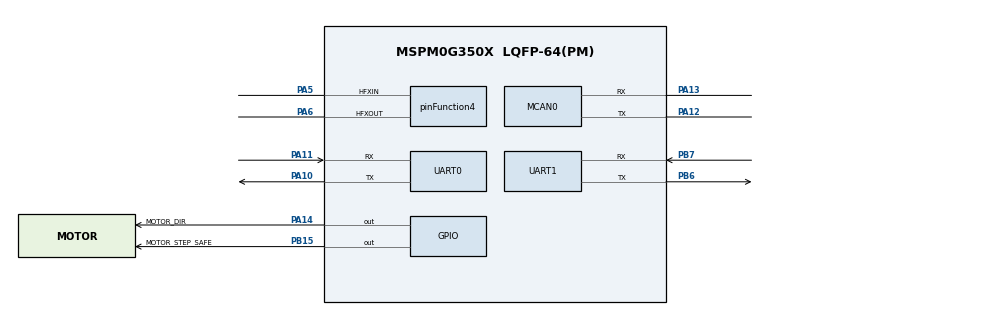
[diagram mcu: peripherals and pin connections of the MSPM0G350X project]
/**
 * @cliArgs --device "MSPM0G350X" --part "Default" --package "LQFP-64(PM)" --product "mspm0_sdk@2.10.00.04"
 * @versions {"tool":"1.27.1+4634"}
 */

/** Import only the system/debug, CAN, and project output modules. */
const Board         = scripting.addModule("/ti/driverlib/Board");
const GPIO          = scripting.addModule("/ti/driverlib/GPIO", {}, false);
const GPIOMotor     = GPIO.addInstance();
const MCAN          = scripting.addModule("/ti/driverlib/MCAN", {}, false);
const MCAN0         = MCAN.addInstance();
const SYSCTL        = scripting.addModule("/ti/driverlib/SYSCTL");
const UART          = scripting.addModule("/ti/driverlib/UART", {}, false);
const UART0         = UART.addInstance();
const UART1         = UART.addInstance();
const ProjectConfig = scripting.addModule("/ti/project_config/ProjectConfig");

/* Keep the validated external 40 MHz clock and 80 MHz HFCLK clock tree. */
const divider9       = system.clockTree["UDIV"];
divider9.divideValue = 2;

const gate7  = system.clockTree["MFCLKGATE"];
gate7.enable = true;

const mux4       = system.clockTree["EXHFMUX"];
mux4.inputSelect = "EXHFMUX_XTAL";

const mux8       = system.clockTree["HSCLKMUX"];
mux8.inputSelect = "HSCLKMUX_SYSPLL2X";

const mux12       = system.clockTree["SYSPLLMUX"];
mux12.inputSelect = "zSYSPLLMUX_HFCLK";

const pinFunction4                       = system.clockTree["HFXT"];
pinFunction4.inputFreq                   = 40;
pinFunction4.enable                      = true;
pinFunction4.peripheral.hfxInPin.$assign = "PA5";
pinFunction4.peripheral.hfxOutPin.$assign = "PA6";

/* CAN0: Classic CAN, 500 kbit/s, normal bus mode, standard ID 0x100 to FIFO0. */
MCAN0.$name                     = "MCAN0";
MCAN0.fdMode                    = false;
MCAN0.brsEnable                 = false;
MCAN0.loopbackMode              = "disabled";
MCAN0.desiredNomRate            = 500;
MCAN0.useCalcNomVal             = true;
MCAN0.lss                       = 2;
MCAN0.stdFiltElem               = "001";
MCAN0.stdFiltType               = "10";
MCAN0.stdFiltID1                = 0x100;
MCAN0.stdFiltID2                = 0x7FF;

/* Classic CAN uses 8-byte data elements; keep active message RAM sections disjoint. */
MCAN0.flesa                     = 8;
MCAN0.txStartAddr                = 16;
MCAN0.txBufNum                   = 3;
MCAN0.txBufElemSize              = "DL_MCAN_ELEM_SIZE_8BYTES";
MCAN0.txEventFIFOStartAddr       = 48;
MCAN0.txEventFIFOSize            = 0;
MCAN0.txEventFIFOWaterMark       = 0;
MCAN0.rxFIFO0startAddr           = 64;
MCAN0.rxFIFO0size                = 3;
MCAN0.rxFIFO0ElemSize            = "DL_MCAN_ELEM_SIZE_8BYTES";
MCAN0.rxFIFO1startAddr           = 112;
MCAN0.rxFIFO1size                = 0;
MCAN0.rxFIFO1ElemSize            = "DL_MCAN_ELEM_SIZE_8BYTES";
MCAN0.rxBufStartAddr             = 112;
MCAN0.rxBufElemSize              = "DL_MCAN_ELEM_SIZE_8BYTES";
MCAN0.peripheral.$assign        = "CANFD0";
MCAN0.peripheral.rxPin.$assign  = "PA13";
MCAN0.peripheral.txPin.$assign  = "PA12";
MCAN0.rxPinConfig.$name         = "ti_driverlib_gpio_MCAN0_RX";
MCAN0.txPinConfig.$name         = "ti_driverlib_gpio_MCAN0_TX";
SYSCTL.CANCLKSource             = "HFCLK";
SYSCTL.clockTreeEn               = true;

/* UART0 boot log: board-verified PA10 TX / PA11 RX at 115200 baud. */
UART0.$name                    = "UART_0";
UART0.enableFIFO               = true;
UART0.enableInternalLoopback   = false;
UART0.targetBaudRate           = 115200;
UART0.peripheral.$assign       = "UART0";
UART0.peripheral.txPin.$assign = "PA10";
UART0.peripheral.rxPin.$assign = "PA11";

/* Motor UART: keep boot logging isolated on UART0 and use UART1 for X42S. */
UART1.$name                    = "UART_1";
UART1.enableFIFO               = true;
UART1.enableInternalLoopback   = false;
UART1.targetBaudRate           = 115200;
UART1.enabledInterrupts        = ["RX"];
UART1.rxFifoThreshold          = "DL_UART_RX_FIFO_LEVEL_ONE_ENTRY";
UART1.peripheral.$assign       = "UART1";
UART1.peripheral.txPin.$assign = "PB6";
UART1.peripheral.rxPin.$assign = "PB7";
UART1.txPinConfig.$name        = "ZDT_UART_TX";
UART1.rxPinConfig.$name        = "ZDT_UART_RX";

/* Motor control pins start as inactive GPIO outputs; no STEP timer is enabled. */
GPIOMotor.$name = "GPIO_MOTOR";
GPIOMotor.associatedPins.create(2);
GPIOMotor.associatedPins[0].$name = "MOTOR_STEP_SAFE";
GPIOMotor.associatedPins[0].direction = "OUTPUT";
GPIOMotor.associatedPins[0].assignedPort = "PORTB";
GPIOMotor.associatedPins[0].assignedPin = "15";
GPIOMotor.associatedPins[0].initialValue = "CLEARED";
GPIOMotor.associatedPins[0].pin.$assign = "PB15";
GPIOMotor.associatedPins[1].$name = "MOTOR_DIR";
GPIOMotor.associatedPins[1].direction = "OUTPUT";
GPIOMotor.associatedPins[1].assignedPort = "PORTA";
GPIOMotor.associatedPins[1].assignedPin = "14";
GPIOMotor.associatedPins[1].initialValue = "CLEARED";
GPIOMotor.associatedPins[1].pin.$assign = "PA14";

/* Preserve the board SWD debug pins and the existing generated-file policy. */
ProjectConfig.genLibDrivers = true;
ProjectConfig.genLinker     = false;
ProjectConfig.genStartup    = false;
ProjectConfig.genOpts       = false;
ProjectConfig.genLibs       = false;

/* Pin solutions retained only for the external clock, SWD and MCAN. */
pinFunction4.peripheral.$suggestSolution           = "SYSCTL";
Board.peripheral.$suggestSolution                  = "DEBUGSS";
Board.peripheral.swclkPin.$suggestSolution         = "PA20";
Board.peripheral.swdioPin.$suggestSolution         = "PA19";
MCAN0.peripheral.$suggestSolution                  = "CANFD0";
MCAN0.peripheral.rxPin.$suggestSolution            = "PA13";
MCAN0.peripheral.txPin.$suggestSolution            = "PA12";
UART1.peripheral.$suggestSolution                  = "UART1";
UART1.peripheral.txPin.$suggestSolution            = "PB6";
UART1.peripheral.rxPin.$suggestSolution            = "PB7";
